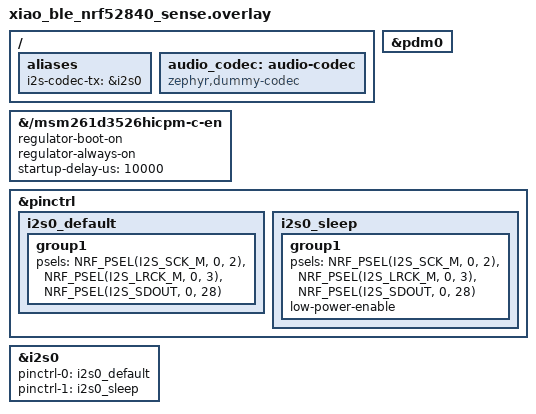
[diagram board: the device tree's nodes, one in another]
/*
 * SPDX-License-Identifier: Apache-2.0
 */

/*
 * Onboard PDM microphone -> gain -> I2S -> MAX98357A amplifier.
 *
 * The amplifier has no control interface, so a dummy codec stands in for the
 * one the sink configures. Wire it to D0 (BCLK), D1 (LRC) and D2 (DIN); the
 * microphone is internal and needs no wiring.
 */

/ {
	aliases {
		i2s-codec-tx = &i2s0;
	};

	audio_codec: audio-codec {
		compatible = "zephyr,dummy-codec";
		status = "okay";
	};
};

/* The microphone's supply has no regulator-boot-on in the board dts, so it is
 * never switched on and the PDM line reads a constant.
 */
&{/msm261d3526hicpm-c-en} {
	regulator-boot-on;
	regulator-always-on;
	startup-delay-us = <10000>;
};

dmic_dev: &pdm0 {
	status = "okay";
};

&pinctrl {
	i2s0_default: i2s0_default {
		group1 {
			psels = <NRF_PSEL(I2S_SCK_M, 0, 2)>,   /* D0 */
				<NRF_PSEL(I2S_LRCK_M, 0, 3)>,  /* D1 */
				<NRF_PSEL(I2S_SDOUT, 0, 28)>;  /* D2 */
		};
	};

	i2s0_sleep: i2s0_sleep {
		group1 {
			psels = <NRF_PSEL(I2S_SCK_M, 0, 2)>,
				<NRF_PSEL(I2S_LRCK_M, 0, 3)>,
				<NRF_PSEL(I2S_SDOUT, 0, 28)>;
			low-power-enable;
		};
	};
};

&i2s0 {
	status = "okay";
	pinctrl-0 = <&i2s0_default>;
	pinctrl-1 = <&i2s0_sleep>;
	pinctrl-names = "default", "sleep";
};
